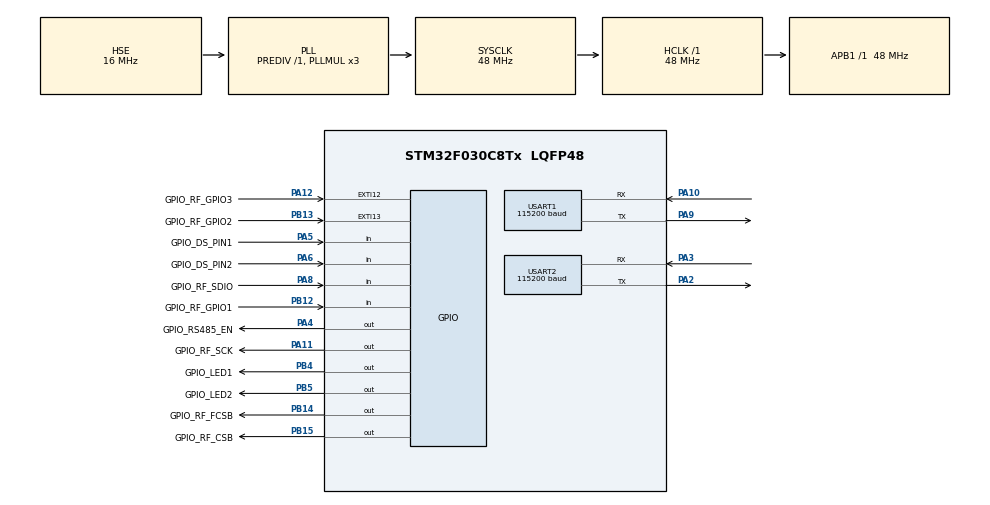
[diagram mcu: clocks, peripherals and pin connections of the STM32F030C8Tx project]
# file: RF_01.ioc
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Mcu.Family=STM32F0
Mcu.Name=STM32F030C8Tx
Mcu.Package=LQFP48
NVIC.EXTI4_15_IRQn=true\:0\:0\:false\:false\:true\:true\:true\:true
NVIC.TIM16_IRQn=true\:0\:0\:false\:false\:true\:true\:true\:true
NVIC.TIM17_IRQn=true\:0\:0\:false\:false\:true\:true\:true\:true
NVIC.USART1_IRQn=true\:0\:0\:true\:false\:true\:true\:true\:true
PA10.Mode=Asynchronous
PA10.Signal=USART1_RX
PA11.GPIO_Label=GPIO_RF_SCK
PA11.GPIO_PuPd=GPIO_NOPULL
PA11.GPIO_Speed=GPIO_SPEED_FREQ_HIGH
PA11.Signal=GPIO_Output
PA12.GPIO_Label=GPIO_RF_GPIO3
PA12.GPIO_PuPd=GPIO_PULLUP
PA12.Signal=GPXTI12
PA13.Mode=Serial_Wire
PA13.Signal=SYS_SWDIO
PA14.Mode=Serial_Wire
PA14.Signal=SYS_SWCLK
PA2.Mode=Asynchronous
PA2.Signal=USART2_TX
PA3.Mode=Asynchronous
PA3.Signal=USART2_RX
PA4.GPIO_Label=GPIO_RS485_EN
PA4.GPIO_Speed=GPIO_SPEED_FREQ_MEDIUM
PA4.Signal=GPIO_Output
PA5.GPIO_Label=GPIO_DS_PIN1
PA5.GPIO_PuPd=GPIO_PULLDOWN
PA5.Signal=GPIO_Input
PA6.GPIO_Label=GPIO_DS_PIN2
PA6.GPIO_PuPd=GPIO_PULLDOWN
PA6.Signal=GPIO_Input
PA8.GPIO_Label=GPIO_RF_SDIO
PA8.Signal=GPIO_Input
PA9.Mode=Asynchronous
PA9.Signal=USART1_TX
PB12.GPIO_Label=GPIO_RF_GPIO1
PB12.GPIO_PuPd=GPIO_PULLUP
PB12.Signal=GPIO_Input
PB13.GPIO_Label=GPIO_RF_GPIO2
PB13.GPIO_PuPd=GPIO_PULLUP
PB13.Signal=GPXTI13
PB14.GPIO_Label=GPIO_RF_FCSB
PB14.GPIO_Speed=GPIO_SPEED_FREQ_HIGH
PB14.Signal=GPIO_Output
PB15.GPIO_Label=GPIO_RF_CSB
PB15.GPIO_Speed=GPIO_SPEED_FREQ_HIGH
PB15.Signal=GPIO_Output
PB4.GPIO_Label=GPIO_LED1
PB4.GPIO_Speed=GPIO_SPEED_FREQ_MEDIUM
PB4.Signal=GPIO_Output
PB5.GPIO_Label=GPIO_LED2
PB5.GPIO_Speed=GPIO_SPEED_FREQ_MEDIUM
PB5.Signal=GPIO_Output
PF0-OSC_IN.Mode=HSE-External-Oscillator
PF0-OSC_IN.Signal=RCC_OSC_IN
PF1-OSC_OUT.Mode=HSE-External-Oscillator
PF1-OSC_OUT.Signal=RCC_OSC_OUT
ProjectManager.HeapSize=0x200
ProjectManager.StackSize=0x400
ProjectManager.TargetToolchain=STM32CubeIDE
RCC.AHBFreq_Value=48000000
RCC.APB1Freq_Value=48000000
RCC.APB1TimFreq_Value=48000000
RCC.HCLKFreq_Value=48000000
RCC.HSE_VALUE=16000000
RCC.PLLMUL=RCC_PLL_MUL3
RCC.PLLSourceVirtual=RCC_PLLSOURCE_HSE
RCC.SYSCLKFreq_VALUE=48000000
RCC.SYSCLKSource=RCC_SYSCLKSOURCE_PLLCLK
TIM16.Period=50-1
TIM16.Prescaler=4800-1
TIM17.Period=36-1
TIM17.Prescaler=4800-1
USART1.BaudRate=115200
USART1.VirtualMode-Asynchronous=VM_ASYNC
USART2.BaudRate=115200
USART2.VirtualMode-Asynchronous=VM_ASYNC
VP_TIM16_VS_ClockSourceINT.Mode=Enable_Timer
VP_TIM17_VS_ClockSourceINT.Mode=Enable_Timer
board=custom

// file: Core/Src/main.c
/* USER CODE BEGIN Header */
/**
  ******************************************************************************
  * @file           : main.c
  * @brief          : Main program body
  ******************************************************************************
  * @attention
  *
  * <h2><center>&copy; Copyright (c) 2023 STMicroelectronics.
  * All rights reserved.</center></h2>
  *
  * This software component is licensed by ST under BSD 3-Clause license,
  * the "License"; You may not use this file except in compliance with the
  * License. You may obtain a copy of the License at:
  *                        opensource.org/licenses/BSD-3-Clause
  *
  ******************************************************************************
  */
/* USER CODE END Header */
#include "main.h"

/* USER CODE BEGIN Includes */
#include "bsp.h"
/* USER CODE END Includes */

TIM_HandleTypeDef htim16;
TIM_HandleTypeDef htim17;

UART_HandleTypeDef huart1;
UART_HandleTypeDef huart2;

void SystemClock_Config(void);
static void MX_GPIO_Init(void);
static void MX_USART1_UART_Init(void);
static void MX_USART2_UART_Init(void);
static void MX_TIM17_Init(void);
static void MX_TIM16_Init(void);
/* USER CODE BEGIN PFP */
// extern void messageQueueTest(void);
extern void stateActuator(void);
/* USER CODE END PFP */

int main(void)
{
  /* USER CODE BEGIN 1 */
  // uint8_t buffer[256] = { 0 };
  // uint32_t bufferSize = 0;
  /* USER CODE END 1 */

  /* MCU Configuration--------------------------------------------------------*/

  /* Reset of all peripherals, Initializes the Flash interface and the Systick. */
  HAL_Init();

  /* Configure the system clock */
  SystemClock_Config();

  /* Initialize all configured peripherals */
  MX_GPIO_Init();
  MX_USART1_UART_Init();
  MX_USART2_UART_Init();
  MX_TIM17_Init();
  MX_TIM16_Init();
  /* USER CODE BEGIN 2 */
  bspInit();
#if (BSP_TEST_ENABLE == 0)
  stateActuator();
#endif
//  messageQueueTest();
  /* USER CODE END 2 */

  /* Infinite loop */
  while (1)
  {

    /* USER CODE BEGIN 3 */
#if BSP_TEST_ENABLE
	bspTest();
#endif
//	bufferSize = uartGetData(BSP_TTL_CHANNEL1, buffer, 256);
//	if (bufferSize)
//	{
//		/* send the buffer data to uart1 */
//		 uartSendData(BSP_TTL_CHANNEL1, buffer, bufferSize);
//		 HAL_Delay_nMs(1000);
//    RF_sendMessage(unsigned char *message, unsigned char messageLen);
//
//		/* reset the value */
//		bufferSize = 0;
//		uartResetData(BSP_TTL_CHANNEL1);
//	}
  }
  /* USER CODE END 3 */
}

void SystemClock_Config(void)
{
  RCC_OscInitTypeDef RCC_OscInitStruct = {0};
  RCC_ClkInitTypeDef RCC_ClkInitStruct = {0};
  RCC_PeriphCLKInitTypeDef PeriphClkInit = {0};

  /** Initializes the RCC Oscillators according to the specified parameters
  * in the RCC_OscInitTypeDef structure.
  */
  RCC_OscInitStruct.OscillatorType = RCC_OSCILLATORTYPE_HSE;
  RCC_OscInitStruct.HSEState = RCC_HSE_ON;
  RCC_OscInitStruct.PLL.PLLState = RCC_PLL_ON;
  RCC_OscInitStruct.PLL.PLLSource = RCC_PLLSOURCE_HSE;
  RCC_OscInitStruct.PLL.PLLMUL = RCC_PLL_MUL3;
  RCC_OscInitStruct.PLL.PREDIV = RCC_PREDIV_DIV1;
  if (HAL_RCC_OscConfig(&RCC_OscInitStruct) != HAL_OK)
  {
    Error_Handler();
  }
  /** Initializes the CPU, AHB and APB buses clocks
  */
  RCC_ClkInitStruct.ClockType = RCC_CLOCKTYPE_HCLK|RCC_CLOCKTYPE_SYSCLK
                              |RCC_CLOCKTYPE_PCLK1;
  RCC_ClkInitStruct.SYSCLKSource = RCC_SYSCLKSOURCE_PLLCLK;
  RCC_ClkInitStruct.AHBCLKDivider = RCC_SYSCLK_DIV1;
  RCC_ClkInitStruct.APB1CLKDivider = RCC_HCLK_DIV1;

  if (HAL_RCC_ClockConfig(&RCC_ClkInitStruct, FLASH_LATENCY_1) != HAL_OK)
  {
    Error_Handler();
  }
  PeriphClkInit.PeriphClockSelection = RCC_PERIPHCLK_USART1;
  PeriphClkInit.Usart1ClockSelection = RCC_USART1CLKSOURCE_PCLK1;
  if (HAL_RCCEx_PeriphCLKConfig(&PeriphClkInit) != HAL_OK)
  {
    Error_Handler();
  }
}

static void MX_TIM16_Init(void)
{

  htim16.Instance = TIM16;
  htim16.Init.Prescaler = 4800-1;
  htim16.Init.CounterMode = TIM_COUNTERMODE_UP;
  htim16.Init.Period = 50-1;
  htim16.Init.ClockDivision = TIM_CLOCKDIVISION_DIV1;
  htim16.Init.RepetitionCounter = 0;
  htim16.Init.AutoReloadPreload = TIM_AUTORELOAD_PRELOAD_DISABLE;
  if (HAL_TIM_Base_Init(&htim16) != HAL_OK)
  {
    Error_Handler();
  }

}

static void MX_TIM17_Init(void)
{

  htim17.Instance = TIM17;
  htim17.Init.Prescaler = 4800-1;
  htim17.Init.CounterMode = TIM_COUNTERMODE_UP;
  htim17.Init.Period = 36-1;
  htim17.Init.ClockDivision = TIM_CLOCKDIVISION_DIV1;
  htim17.Init.RepetitionCounter = 0;
  htim17.Init.AutoReloadPreload = TIM_AUTORELOAD_PRELOAD_DISABLE;
  if (HAL_TIM_Base_Init(&htim17) != HAL_OK)
  {
    Error_Handler();
  }

}

static void MX_USART1_UART_Init(void)
{

  huart1.Instance = USART1;
  huart1.Init.BaudRate = 115200;
  huart1.Init.WordLength = UART_WORDLENGTH_8B;
  huart1.Init.StopBits = UART_STOPBITS_1;
  huart1.Init.Parity = UART_PARITY_NONE;
  huart1.Init.Mode = UART_MODE_TX_RX;
  huart1.Init.HwFlowCtl = UART_HWCONTROL_NONE;
  huart1.Init.OverSampling = UART_OVERSAMPLING_16;
  huart1.Init.OneBitSampling = UART_ONE_BIT_SAMPLE_DISABLE;
  huart1.AdvancedInit.AdvFeatureInit = UART_ADVFEATURE_NO_INIT;
  if (HAL_UART_Init(&huart1) != HAL_OK)
  {
    Error_Handler();
  }

}

static void MX_USART2_UART_Init(void)
{

  huart2.Instance = USART2;
  huart2.Init.BaudRate = 115200;
  huart2.Init.WordLength = UART_WORDLENGTH_8B;
  huart2.Init.StopBits = UART_STOPBITS_1;
  huart2.Init.Parity = UART_PARITY_NONE;
  huart2.Init.Mode = UART_MODE_TX_RX;
  huart2.Init.HwFlowCtl = UART_HWCONTROL_NONE;
  huart2.Init.OverSampling = UART_OVERSAMPLING_16;
  huart2.Init.OneBitSampling = UART_ONE_BIT_SAMPLE_DISABLE;
  huart2.AdvancedInit.AdvFeatureInit = UART_ADVFEATURE_NO_INIT;
  if (HAL_UART_Init(&huart2) != HAL_OK)
  {
    Error_Handler();
  }

}

static void MX_GPIO_Init(void)
{
  GPIO_InitTypeDef GPIO_InitStruct = {0};

  /* GPIO Ports Clock Enable */
  __HAL_RCC_GPIOF_CLK_ENABLE();
  __HAL_RCC_GPIOA_CLK_ENABLE();
  __HAL_RCC_GPIOB_CLK_ENABLE();

  /*Configure GPIO pin Output Level */
  HAL_GPIO_WritePin(GPIOA, GPIO_RS485_EN_Pin|GPIO_RF_SCK_Pin, GPIO_PIN_RESET);

  /*Configure GPIO pin Output Level */
  HAL_GPIO_WritePin(GPIOB, GPIO_RF_FCSB_Pin|GPIO_RF_CSB_Pin|GPIO_LED1_Pin|GPIO_LED2_Pin, GPIO_PIN_RESET);

  /*Configure GPIO pin : GPIO_RS485_EN_Pin */
  GPIO_InitStruct.Pin = GPIO_RS485_EN_Pin;
  GPIO_InitStruct.Mode = GPIO_MODE_OUTPUT_PP;
  GPIO_InitStruct.Pull = GPIO_NOPULL;
  GPIO_InitStruct.Speed = GPIO_SPEED_FREQ_MEDIUM;
  HAL_GPIO_Init(GPIO_RS485_EN_GPIO_Port, &GPIO_InitStruct);

  /*Configure GPIO pins : GPIO_DS_PIN1_Pin GPIO_DS_PIN2_Pin */
  GPIO_InitStruct.Pin = GPIO_DS_PIN1_Pin|GPIO_DS_PIN2_Pin;
  GPIO_InitStruct.Mode = GPIO_MODE_INPUT;
  GPIO_InitStruct.Pull = GPIO_PULLDOWN;
  HAL_GPIO_Init(GPIOA, &GPIO_InitStruct);

  /*Configure GPIO pin : GPIO_RF_GPIO1_Pin */
  GPIO_InitStruct.Pin = GPIO_RF_GPIO1_Pin;
  GPIO_InitStruct.Mode = GPIO_MODE_INPUT;
  GPIO_InitStruct.Pull = GPIO_PULLUP;
  HAL_GPIO_Init(GPIO_RF_GPIO1_GPIO_Port, &GPIO_InitStruct);

  /*Configure GPIO pin : GPIO_RF_GPIO2_Pin */
  GPIO_InitStruct.Pin = GPIO_RF_GPIO2_Pin;
  GPIO_InitStruct.Mode = GPIO_MODE_IT_RISING;
  GPIO_InitStruct.Pull = GPIO_PULLUP;
  HAL_GPIO_Init(GPIO_RF_GPIO2_GPIO_Port, &GPIO_InitStruct);

  /*Configure GPIO pins : GPIO_RF_FCSB_Pin GPIO_RF_CSB_Pin */
  GPIO_InitStruct.Pin = GPIO_RF_FCSB_Pin|GPIO_RF_CSB_Pin;
  GPIO_InitStruct.Mode = GPIO_MODE_OUTPUT_PP;
  GPIO_InitStruct.Pull = GPIO_NOPULL;
  GPIO_InitStruct.Speed = GPIO_SPEED_FREQ_HIGH;
  HAL_GPIO_Init(GPIOB, &GPIO_InitStruct);

  /*Configure GPIO pin : GPIO_RF_SDIO_Pin */
  GPIO_InitStruct.Pin = GPIO_RF_SDIO_Pin;
  GPIO_InitStruct.Mode = GPIO_MODE_INPUT;
  GPIO_InitStruct.Pull = GPIO_NOPULL;
  HAL_GPIO_Init(GPIO_RF_SDIO_GPIO_Port, &GPIO_InitStruct);

  /*Configure GPIO pin : GPIO_RF_SCK_Pin */
  GPIO_InitStruct.Pin = GPIO_RF_SCK_Pin;
  GPIO_InitStruct.Mode = GPIO_MODE_OUTPUT_PP;
  GPIO_InitStruct.Pull = GPIO_NOPULL;
  GPIO_InitStruct.Speed = GPIO_SPEED_FREQ_HIGH;
  HAL_GPIO_Init(GPIO_RF_SCK_GPIO_Port, &GPIO_InitStruct);

  /*Configure GPIO pin : GPIO_RF_GPIO3_Pin */
  GPIO_InitStruct.Pin = GPIO_RF_GPIO3_Pin;
  GPIO_InitStruct.Mode = GPIO_MODE_IT_RISING;
  GPIO_InitStruct.Pull = GPIO_PULLUP;
  HAL_GPIO_Init(GPIO_RF_GPIO3_GPIO_Port, &GPIO_InitStruct);

  /*Configure GPIO pins : GPIO_LED1_Pin GPIO_LED2_Pin */
  GPIO_InitStruct.Pin = GPIO_LED1_Pin|GPIO_LED2_Pin;
  GPIO_InitStruct.Mode = GPIO_MODE_OUTPUT_PP;
  GPIO_InitStruct.Pull = GPIO_NOPULL;
  GPIO_InitStruct.Speed = GPIO_SPEED_FREQ_MEDIUM;
  HAL_GPIO_Init(GPIOB, &GPIO_InitStruct);

  /* EXTI interrupt init*/
  HAL_NVIC_SetPriority(EXTI4_15_IRQn, 0, 0);
  HAL_NVIC_EnableIRQ(EXTI4_15_IRQn);

}

void Error_Handler(void)
{
  __disable_irq();
  while (1)
  {
  }
}

/************************ (C) COPYRIGHT STMicroelectronics *****END OF FILE****/
